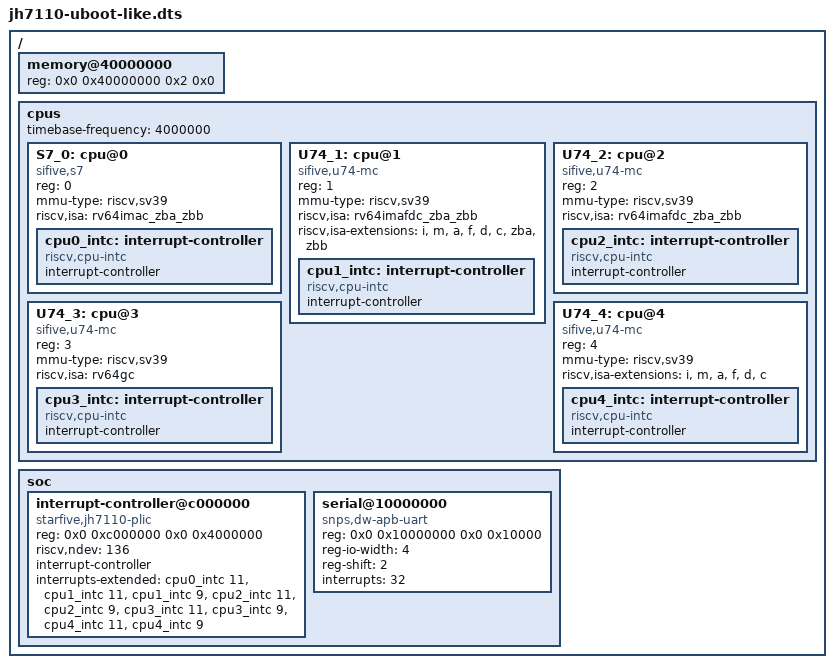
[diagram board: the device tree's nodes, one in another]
/dts-v1/;
/*
 * A hand-written tree in the shape of U-Boot's control tree for the JH7110
 * (BUG-338): the S7 monitor core is enabled and has an mmu-type, and only its
 * riscv,isa (rv64imac, no F or D) says it cannot run the system.
 */
/ {
	#address-cells = <2>;
	#size-cells = <2>;
	memory@40000000 {
		device_type = "memory";
		reg = <0x0 0x40000000 0x2 0x0>;
	};
	cpus {
		#address-cells = <1>;
		#size-cells = <0>;
		timebase-frequency = <4000000>;
		S7_0: cpu@0 {
			compatible = "sifive,s7", "riscv";
			device_type = "cpu";
			reg = <0>;
			status = "okay";
			mmu-type = "riscv,sv39";
			riscv,isa = "rv64imac_zba_zbb";
			cpu0_intc: interrupt-controller {
				#interrupt-cells = <1>;
				interrupt-controller;
				compatible = "riscv,cpu-intc";
			};
		};
		U74_1: cpu@1 {
			compatible = "sifive,u74-mc", "riscv";
			device_type = "cpu";
			reg = <1>;
			status = "okay";
			mmu-type = "riscv,sv39";
			riscv,isa = "rv64imafdc_zba_zbb";
			riscv,isa-extensions = "i", "m", "a", "f", "d", "c", "zba", "zbb";
			cpu1_intc: interrupt-controller {
				#interrupt-cells = <1>;
				interrupt-controller;
				compatible = "riscv,cpu-intc";
			};
		};
		U74_2: cpu@2 {
			compatible = "sifive,u74-mc", "riscv";
			device_type = "cpu";
			reg = <2>;
			status = "okay";
			mmu-type = "riscv,sv39";
			riscv,isa = "rv64imafdc_zba_zbb";
			cpu2_intc: interrupt-controller {
				#interrupt-cells = <1>;
				interrupt-controller;
				compatible = "riscv,cpu-intc";
			};
		};
		U74_3: cpu@3 {
			compatible = "sifive,u74-mc", "riscv";
			device_type = "cpu";
			reg = <3>;
			status = "okay";
			mmu-type = "riscv,sv39";
			riscv,isa = "rv64gc";
			cpu3_intc: interrupt-controller {
				#interrupt-cells = <1>;
				interrupt-controller;
				compatible = "riscv,cpu-intc";
			};
		};
		U74_4: cpu@4 {
			compatible = "sifive,u74-mc", "riscv";
			device_type = "cpu";
			reg = <4>;
			status = "okay";
			mmu-type = "riscv,sv39";
			riscv,isa-extensions = "i", "m", "a", "f", "d", "c";
			cpu4_intc: interrupt-controller {
				#interrupt-cells = <1>;
				interrupt-controller;
				compatible = "riscv,cpu-intc";
			};
		};
	};
	soc {
		#address-cells = <2>;
		#size-cells = <2>;
		ranges;
		interrupt-controller@c000000 {
			compatible = "starfive,jh7110-plic", "sifive,plic-1.0.0";
			reg = <0x0 0xc000000 0x0 0x4000000>;
			riscv,ndev = <136>;
			interrupt-controller;
			interrupts-extended = <&cpu0_intc 11>,
				<&cpu1_intc 11>, <&cpu1_intc 9>,
				<&cpu2_intc 11>, <&cpu2_intc 9>,
				<&cpu3_intc 11>, <&cpu3_intc 9>,
				<&cpu4_intc 11>, <&cpu4_intc 9>;
		};
		serial@10000000 {
			compatible = "snps,dw-apb-uart";
			reg = <0x0 0x10000000 0x0 0x10000>;
			reg-io-width = <4>;
			reg-shift = <2>;
			interrupts = <32>;
		};
	};
};
